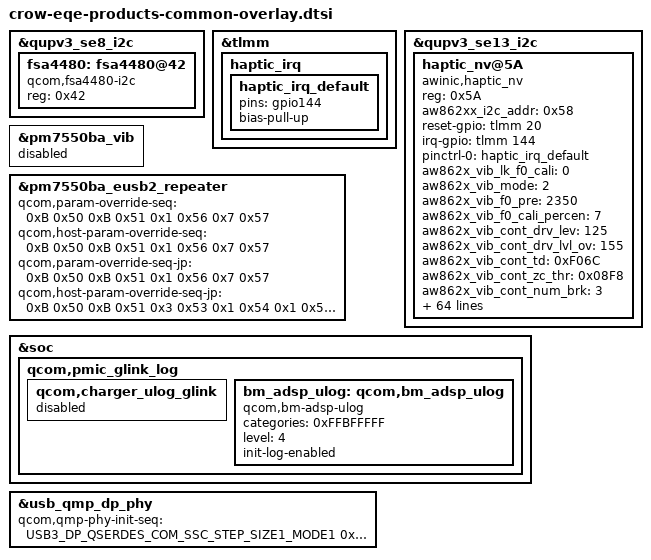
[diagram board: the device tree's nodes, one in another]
/* Copyright (c) 2023, The Linux Foundation. All rights reserved.
 *
 * This program is free software; you can redistribute it and/or modify
 * it under the terms of the GNU General Public License version 2 and
 * only version 2 as published by the Free Software Foundation.
 *
 * This program is distributed in the hope that it will be useful,
 * but WITHOUT ANY WARRANTY; without even the implied warranty of
 * MERCHANTABILITY or FITNESS FOR A PARTICULAR PURPOSE.  See the
 * GNU General Public License for more details.
 */

/*
   This file is used for all rtwo products include prc, row, na etc.
*/

#include "crow-moto-common-overlay-base.dtsi"
#include "crow-moto-common-overlay.dtsi"
#include <dt-bindings/phy/qcom,usb3-4nm-qmp-combo.h>

&qupv3_se8_i2c {
    status = "ok";
    fsa4480: fsa4480@42 {
        compatible = "qcom,fsa4480-i2c";
        reg = <0x42>;
    };
};
&tlmm{
    haptic_irq {
        haptic_irq_default: haptic_irq_default {
            pins = "gpio144";
            bias-pull-up;
        };
    };
};
&qupv3_se13_i2c {
  status = "ok";
  haptic_nv@5A{
		compatible = "awinic,haptic_nv";
		reg = < 0x5A >;
		aw862xx_i2c_addr = < 0x58 >;
		/* aw8624x_no_reset; */
		reset-gpio = <&tlmm 20 0>;
		irq-gpio = <&tlmm 144 0>;
		pinctrl-names = "default";
		pinctrl-0 = <&haptic_irq_default>;
/****************************** aw862x ******************************/
		aw862x_vib_lk_f0_cali = < 0 >;
		aw862x_vib_mode = < 2 >; /* mode: RAM -> 2; CONT -> 3 */
		aw862x_vib_f0_pre = < 2350 >;
		aw862x_vib_f0_cali_percen = < 7 >;
		aw862x_vib_cont_drv_lev = < 125 >;
		aw862x_vib_cont_drv_lvl_ov = < 155 >;
		aw862x_vib_cont_td = < 0xF06C >;
		aw862x_vib_cont_zc_thr = < 0x08F8 >;
		aw862x_vib_cont_num_brk = < 3 >;
		aw862x_vib_f0_coeff = < 260 >; /* Don't modify it */
		aw862x_vib_brake_cont_config = < 1 1 90 42 20 5 2 2 0 0 0 0 0 0 0 0 0 0 0 0 0 0 0 0 >;
		aw862x_vib_f0_trace_parameter = < 0x05 0x03 0x02 0x0F >;
		aw862x_vib_bemf_config = < 0x10 0x08 0x23 0xF8 >;
		aw862x_vib_sw_brake = < 0x2C 0x08 >; /* cont brake, other brake */
		aw862x_vib_trig_config = < 0 1 0 1 1 >;
		aw862x_vib_tset = < 0x11 >;
		aw862x_vib_duration_time = < 20 30 60 >;
/***************************** aw862xx ******************************/
		aw862xx_gain_bypass = < 1 >;
		aw862xx_vib_lk_f0_cali = < 0 >;
		aw862xx_vib_mode = < 2 >; /* mode: RAM -> 2; CONT -> 3 */
		aw862xx_vib_f0_pre = < 2350 >;
		aw862xx_vib_f0_cali_percen = < 7 >;
		aw862xx_vib_cont_drv1_lvl = < 0x7F >;
		aw862xx_vib_lra_vrms = < 1000 >; /* Motor rated voltage, mV */
		aw862xx_vib_cont_brk_time = < 0x06 >;
		aw862xx_vib_cont_brk_gain = < 0x08 >;
		aw862xx_vib_cont_drv1_time = < 0x04 >;
		aw862xx_vib_cont_drv2_time = < 0x14 >;
		aw862xx_vib_cont_track_margin = < 0x0F >;
		aw862xx_vib_d2s_gain = < 0x05 >;
		aw862xx_vib_trig_config = < 0 0 0 1 0 2 0
					    0 0 0 1 0 2 0
					    0 0 0 1 0 2 0 >;
		aw862xx_vib_duration_time = < 20 30 60 >;
		aw862xx_vib_is_enabled_track_en;
		/* aw862xx_vib_is_enabled_auto_brk; */
/***************************** aw8623x ******************************/
		aw8623x_gain_bypass = < 1 >;
		aw8623x_vib_lk_f0_cali = < 0 >;
		aw8623x_vib_mode = < 2 >; /* mode: RAM -> 2; CONT -> 3 */
		aw8623x_vib_f0_pre = < 2350 >;
		aw8623x_vib_f0_cali_percen = < 7 >;
		aw8623x_vib_cont_drv1_lvl = < 0x7F >;
		aw8623x_vib_lra_vrms = < 1000 >; /* Motor rated voltage, mV */
		aw8623x_vib_cont_brk_time = < 0x06 >;
		aw8623x_vib_cont_brk_gain = < 0x08 >;
		aw8623x_vib_cont_drv1_time = < 0x04 >;
		aw8623x_vib_cont_drv2_time = < 0x14 >;
		aw8623x_vib_cont_track_margin = < 0x0F >;
		aw8623x_vib_d2s_gain = < 0x05 >;
		aw8623x_vib_trig_config = < 0 0 0 1 0 2 0
					    0 0 0 1 0 2 0
					    0 0 0 1 0 2 0 >;
		aw8623x_vib_duration_time = < 20 30 60 >;
		aw8623x_vib_is_enabled_track_en;
		/* aw8623x_vib_is_enabled_auto_brk; */
/***************************** aw8624x ******************************/
		aw8624x_gain_bypass = < 1 >;
		aw8624x_vib_lk_f0_cali = < 0 >;
		aw8624x_vib_mode = < 2 >; /* mode: RAM -> 2; CONT -> 3 */
		aw8624x_vib_f0_pre = < 2350 >;
		aw8624x_vib_f0_cali_percen = < 15 >;
		aw8624x_vib_cont_drv1_lvl = < 0x7F >;
		aw8624x_vib_lra_vrms = < 1000 >; /* Motor rated voltage, mV */
		aw8624x_vib_cont_brk_time = < 0x06 >;
		aw8624x_vib_cont_brk_gain = < 0x08 >;
		aw8624x_vib_cont_drv1_time = < 0x04 >;
		aw8624x_vib_cont_drv2_time = < 0x14 >;
		aw8624x_vib_cont_track_margin = < 0x0F >;
		aw8624x_vib_d2s_gain = < 0x05 >;
		aw8624x_vib_f0_d2s_gain = < 0x01 >;
		aw8624x_vib_trig_config = < 0 0 0 1 0 2 0
					    0 0 0 1 0 2 0
					    0 0 0 1 0 2 0 >;
		aw8624x_vib_duration_time = < 20 30 60 >;
		aw8624x_vib_is_enabled_track_en;
		aw8624x_vib_is_enabled_smart_loop;
		aw8624x_vib_is_enabled_inter_brake;
		/* aw8624x_vib_is_enabled_auto_brk; */
		status = "okay";
	};
};

&pm7550ba_vib {
        status = "disabled";
};
&pm7550ba_eusb2_repeater {
	qcom,param-override-seq =
		/* <value reg_offset> */
		/* Adjust HS trasmit amplitude */
		/* USB2 crossover */
		<0xB 0x50
		/* IUSB2 */
		 0xB 0x51
		/* EQU */
		 0x1 0x56
		/*PREEM*/
		 0x7 0x57
		>;
	qcom,host-param-override-seq =
		/* <value reg_offset> */
		/* Adjust HS trasmit amplitude */
		/* USB2 crossover */
		<0xB 0x50
		/* IUSB2 */
		 0xB 0x51
		/* EQU */
		 0x1 0x56
		/*PREEM*/
		 0x7 0x57
		>;
	qcom,param-override-seq-jp =
		/* <value reg_offset> */
		/* Adjust HS trasmit amplitude */
		/* USB2 crossover */
		<0xB 0x50
		/* IUSB2 */
		 0xB 0x51
		/* EQU */
		 0x1 0x56
		/*PREEM*/
		 0x7 0x57
		>;
	qcom,host-param-override-seq-jp =
		/* <value reg_offset> */
		/* Adjust HS trasmit amplitude */
		/* USB2 crossover */
		<0xB 0x50
		/* IUSB2 */
		 0xB 0x51
		/* hsdisc */
		 0x3 0x53
		/* squelch */
		 0x1 0x54
		/* EQU */
		 0x1 0x56
		/*PREEM*/
		 0x7 0x57
		>;
};

&soc {
        qcom,pmic_glink_log {
                qcom,charger_ulog_glink {
                        status = "disabled";
                };
                bm_adsp_ulog: qcom,bm_adsp_ulog {
                        compatible = "qcom,bm-adsp-ulog";
                        categories = <0xFFBFFFFF>;
                        level = <4>;
                        init-log-enabled;
                };
        };
};

		&usb_qmp_dp_phy{
			qcom,qmp-phy-init-seq =
			/* <reg_offset, value> */
		       <USB3_DP_QSERDES_COM_SSC_STEP_SIZE1_MODE1 0x55
			USB3_DP_QSERDES_COM_SSC_STEP_SIZE2_MODE1 0x0E
			USB3_DP_QSERDES_COM_CP_CTRL_MODE1 0x02
			USB3_DP_QSERDES_COM_PLL_RCTRL_MODE1 0x16
			USB3_DP_QSERDES_COM_PLL_CCTRL_MODE1 0x36
			USB3_DP_QSERDES_COM_CORECLK_DIV_MODE1 0x04
			USB3_DP_QSERDES_COM_LOCK_CMP1_MODE1 0x2E
			USB3_DP_QSERDES_COM_LOCK_CMP2_MODE1 0x82
			USB3_DP_QSERDES_COM_DEC_START_MODE1 0x04
			USB3_DP_QSERDES_COM_DEC_START_MSB_MODE1 0x01
			USB3_DP_QSERDES_COM_DIV_FRAC_START1_MODE1 0x55
			USB3_DP_QSERDES_COM_DIV_FRAC_START2_MODE1 0xD5
			USB3_DP_QSERDES_COM_DIV_FRAC_START3_MODE1 0x05
			USB3_DP_QSERDES_COM_HSCLK_SEL_1 0x01
			USB3_DP_QSERDES_COM_VCO_TUNE1_MODE1 0x25
			USB3_DP_QSERDES_COM_VCO_TUNE2_MODE1 0x02
			USB3_DP_QSERDES_COM_BIN_VCOCAL_CMP_CODE1_MODE1 0xB7
			USB3_DP_QSERDES_COM_BIN_VCOCAL_CMP_CODE2_MODE1 0x1E
			USB3_DP_QSERDES_COM_BIN_VCOCAL_CMP_CODE1_MODE0 0xB7
			USB3_DP_QSERDES_COM_BIN_VCOCAL_CMP_CODE2_MODE0 0x1E
			USB3_DP_QSERDES_COM_SSC_STEP_SIZE1_MODE0 0x55
			USB3_DP_QSERDES_COM_SSC_STEP_SIZE2_MODE0 0x0E
			USB3_DP_QSERDES_COM_CP_CTRL_MODE0 0x02
			USB3_DP_QSERDES_COM_PLL_RCTRL_MODE0 0x16
			USB3_DP_QSERDES_COM_PLL_CCTRL_MODE0 0x36
			USB3_DP_QSERDES_COM_LOCK_CMP1_MODE0 0x12
			USB3_DP_QSERDES_COM_LOCK_CMP2_MODE0 0x34
			USB3_DP_QSERDES_COM_DEC_START_MODE0 0x04
			USB3_DP_QSERDES_COM_DEC_START_MSB_MODE0 0x01
			USB3_DP_QSERDES_COM_DIV_FRAC_START1_MODE0 0x55
			USB3_DP_QSERDES_COM_DIV_FRAC_START2_MODE0 0xD5
			USB3_DP_QSERDES_COM_DIV_FRAC_START3_MODE0 0x05
			USB3_DP_QSERDES_COM_VCO_TUNE1_MODE0 0x25
			USB3_DP_QSERDES_COM_VCO_TUNE2_MODE0 0x02
			USB3_DP_QSERDES_COM_BG_TIMER 0x0E
			USB3_DP_QSERDES_COM_SSC_EN_CENTER 0x01
			USB3_DP_QSERDES_COM_SSC_PER1 0x31
			USB3_DP_QSERDES_COM_SSC_PER2 0x01
			USB3_DP_QSERDES_COM_SYSCLK_BUF_ENABLE 0x0C
			USB3_DP_QSERDES_COM_SYSCLK_EN_SEL 0x1A
			USB3_DP_QSERDES_COM_LOCK_CMP_CFG 0x14
			USB3_DP_QSERDES_COM_VCO_TUNE_MAP 0x04
			USB3_DP_QSERDES_COM_CORE_CLK_EN 0x20
			USB3_DP_QSERDES_COM_CMN_CONFIG_1 0x04
			USB3_DP_QSERDES_COM_AUTO_GAIN_ADJ_CTRL_1 0xB6
			USB3_DP_QSERDES_COM_AUTO_GAIN_ADJ_CTRL_2 0x4B
			USB3_DP_QSERDES_COM_AUTO_GAIN_ADJ_CTRL_3 0x37
			USB3_DP_QSERDES_COM_ADDITIONAL_MISC 0x0C
			USB3_DP_QSERDES_TXA_TX_DRV_LVL 0x2f
			USB3_DP_QSERDES_TXA_RES_CODE_LANE_TX 0x00
			USB3_DP_QSERDES_TXA_RES_CODE_LANE_RX 0x00
			USB3_DP_QSERDES_TXA_RES_CODE_LANE_OFFSET_TX 0x1F
			USB3_DP_QSERDES_TXA_RES_CODE_LANE_OFFSET_RX 0x09
			USB3_DP_QSERDES_TXA_LANE_MODE_1 0xF5
			USB3_DP_QSERDES_TXA_LANE_MODE_3 0x3F
			USB3_DP_QSERDES_TXA_LANE_MODE_4 0x3F
			USB3_DP_QSERDES_TXA_LANE_MODE_5 0x5F
			USB3_DP_QSERDES_TXA_RCV_DETECT_LVL_2 0x12
			USB3_DP_QSERDES_TXA_PI_QEC_CTRL 0x21
			USB3_DP_QSERDES_RXA_UCDR_FO_GAIN 0x0A
			USB3_DP_QSERDES_RXA_UCDR_SO_GAIN 0x06
			USB3_DP_QSERDES_RXA_UCDR_FASTLOCK_FO_GAIN 0x2F
			USB3_DP_QSERDES_RXA_UCDR_SO_SATURATION_AND_ENABLE 0x7F
			USB3_DP_QSERDES_RXA_UCDR_FASTLOCK_COUNT_LOW 0xFF
			USB3_DP_QSERDES_RXA_UCDR_FASTLOCK_COUNT_HIGH 0x0F
			USB3_DP_QSERDES_RXA_UCDR_PI_CONTROLS 0x99
			USB3_DP_QSERDES_RXA_UCDR_SB2_THRESH1 0x08
			USB3_DP_QSERDES_RXA_UCDR_SB2_THRESH2 0x08
			USB3_DP_QSERDES_RXA_UCDR_SB2_GAIN1 0x00
			USB3_DP_QSERDES_RXA_UCDR_SB2_GAIN2 0x08
			USB3_DP_QSERDES_RXA_AUX_DATA_TCOARSE_TFINE 0xA0
			USB3_DP_QSERDES_RXA_VGA_CAL_CNTRL1 0x54
			USB3_DP_QSERDES_RXA_VGA_CAL_CNTRL2 0x0F
			USB3_DP_QSERDES_RXA_GM_CAL 0x13
			USB3_DP_QSERDES_RXA_RX_EQU_ADAPTOR_CNTRL2 0x0F
			USB3_DP_QSERDES_RXA_RX_EQU_ADAPTOR_CNTRL3 0x4A
			USB3_DP_QSERDES_RXA_RX_EQU_ADAPTOR_CNTRL4 0x0A
			USB3_DP_QSERDES_RXA_RX_IDAC_TSETTLE_LOW 0x07
			USB3_DP_QSERDES_RXA_RX_IDAC_TSETTLE_HIGH 0x00
			USB3_DP_QSERDES_RXA_RX_EQ_OFFSET_ADAPTOR_CNTRL1 0x47
			USB3_DP_QSERDES_RXA_SIGDET_CNTRL 0x04
			USB3_DP_QSERDES_RXA_SIGDET_DEGLITCH_CNTRL 0x0E
			USB3_DP_QSERDES_RXA_RX_MODE_00_LOW 0x3F
			USB3_DP_QSERDES_RXA_RX_MODE_00_HIGH 0xFF
			USB3_DP_QSERDES_RXA_RX_MODE_00_HIGH2 0xFF
			USB3_DP_QSERDES_RXA_RX_MODE_00_HIGH3 0xDF
			USB3_DP_QSERDES_RXA_RX_MODE_00_HIGH4 0xFE
			USB3_DP_QSERDES_RXA_RX_MODE_01_LOW 0xDC
			USB3_DP_QSERDES_RXA_RX_MODE_01_HIGH 0x5C
			USB3_DP_QSERDES_RXA_RX_MODE_01_HIGH2 0x9C
			USB3_DP_QSERDES_RXA_RX_MODE_01_HIGH3 0x1D
			USB3_DP_QSERDES_RXA_RX_MODE_01_HIGH4 0x09
			USB3_DP_QSERDES_RXA_DFE_EN_TIMER 0x04
			USB3_DP_QSERDES_RXA_DFE_CTLE_POST_CAL_OFFSET 0x38
			USB3_DP_QSERDES_RXA_DCC_CTRL1 0x0C
			USB3_DP_QSERDES_RXA_VTH_CODE 0x10
			USB3_DP_QSERDES_RXA_SIGDET_CAL_CTRL1 0x14
			USB3_DP_QSERDES_RXA_SIGDET_CAL_TRIM 0x08
			USB3_DP_QSERDES_TXB_TX_DRV_LVL 0x2f
			USB3_DP_QSERDES_TXB_RES_CODE_LANE_TX 0x00
			USB3_DP_QSERDES_TXB_RES_CODE_LANE_RX 0x00
			USB3_DP_QSERDES_TXB_RES_CODE_LANE_OFFSET_TX 0x1F
			USB3_DP_QSERDES_TXB_RES_CODE_LANE_OFFSET_RX 0x09
			USB3_DP_QSERDES_TXB_LANE_MODE_1 0xF5
			USB3_DP_QSERDES_TXB_LANE_MODE_3 0x3F
			USB3_DP_QSERDES_TXB_LANE_MODE_4 0x3F
			USB3_DP_QSERDES_TXB_LANE_MODE_5 0x5F
			USB3_DP_QSERDES_TXB_RCV_DETECT_LVL_2 0x12
			USB3_DP_QSERDES_TXB_PI_QEC_CTRL 0x05
			USB3_DP_QSERDES_RXB_UCDR_FO_GAIN 0x0A
			USB3_DP_QSERDES_RXB_UCDR_SO_GAIN 0x06
			USB3_DP_QSERDES_RXB_UCDR_FASTLOCK_FO_GAIN 0x2F
			USB3_DP_QSERDES_RXB_UCDR_SO_SATURATION_AND_ENABLE 0x7F
			USB3_DP_QSERDES_RXB_UCDR_FASTLOCK_COUNT_LOW 0xFF
			USB3_DP_QSERDES_RXB_UCDR_FASTLOCK_COUNT_HIGH 0x0F
			USB3_DP_QSERDES_RXB_UCDR_PI_CONTROLS 0x99
			USB3_DP_QSERDES_RXB_UCDR_SB2_THRESH1 0x08
			USB3_DP_QSERDES_RXB_UCDR_SB2_THRESH2 0x08
			USB3_DP_QSERDES_RXB_UCDR_SB2_GAIN1 0x00
			USB3_DP_QSERDES_RXB_UCDR_SB2_GAIN2 0x08
			USB3_DP_QSERDES_RXB_AUX_DATA_TCOARSE_TFINE 0xA0
			USB3_DP_QSERDES_RXB_VGA_CAL_CNTRL1 0x54
			USB3_DP_QSERDES_RXB_VGA_CAL_CNTRL2 0x0F
			USB3_DP_QSERDES_RXB_GM_CAL 0x13
			USB3_DP_QSERDES_RXB_RX_EQU_ADAPTOR_CNTRL2 0x0F
			USB3_DP_QSERDES_RXB_RX_EQU_ADAPTOR_CNTRL3 0x4A
			USB3_DP_QSERDES_RXB_RX_EQU_ADAPTOR_CNTRL4 0x0A
			USB3_DP_QSERDES_RXB_RX_IDAC_TSETTLE_LOW 0x07
			USB3_DP_QSERDES_RXB_RX_IDAC_TSETTLE_HIGH 0x00
			USB3_DP_QSERDES_RXB_RX_EQ_OFFSET_ADAPTOR_CNTRL1 0x47
			USB3_DP_QSERDES_RXB_SIGDET_CNTRL 0x04
			USB3_DP_QSERDES_RXB_SIGDET_DEGLITCH_CNTRL 0x0E
			USB3_DP_QSERDES_RXB_RX_MODE_00_LOW 0x3F
			USB3_DP_QSERDES_RXB_RX_MODE_00_HIGH 0xFF
			USB3_DP_QSERDES_RXB_RX_MODE_00_HIGH2 0xFF
			USB3_DP_QSERDES_RXB_RX_MODE_00_HIGH3 0xDF
			USB3_DP_QSERDES_RXB_RX_MODE_00_HIGH4 0xFE
			USB3_DP_QSERDES_RXB_RX_MODE_01_LOW 0xDC
			USB3_DP_QSERDES_RXB_RX_MODE_01_HIGH 0x5C
			USB3_DP_QSERDES_RXB_RX_MODE_01_HIGH2 0x9C
			USB3_DP_QSERDES_RXB_RX_MODE_01_HIGH3 0x1D
			USB3_DP_QSERDES_RXB_RX_MODE_01_HIGH4 0x09
			USB3_DP_QSERDES_RXB_DFE_EN_TIMER 0x04
			USB3_DP_QSERDES_RXB_DFE_CTLE_POST_CAL_OFFSET 0x38
			USB3_DP_QSERDES_RXB_DCC_CTRL1 0x0C
			USB3_DP_QSERDES_RXB_VTH_CODE 0x10
			USB3_DP_QSERDES_RXB_SIGDET_CAL_CTRL1 0x14
			USB3_DP_QSERDES_RXB_SIGDET_CAL_TRIM 0x08
			USB3_DP_PCS_LOCK_DETECT_CONFIG1 0xC4
			USB3_DP_PCS_LOCK_DETECT_CONFIG2 0x89
			USB3_DP_PCS_LOCK_DETECT_CONFIG3 0x20
			USB3_DP_PCS_LOCK_DETECT_CONFIG6 0x13
			USB3_DP_PCS_REFGEN_REQ_CONFIG1 0x21
			USB3_DP_PCS_G12S1_TXMGN_V0 0x18
			USB3_DP_PCS_RX_SIGDET_LVL 0x99
			USB3_DP_PCS_RCVR_DTCT_DLY_P1U2_L 0xE7
			USB3_DP_PCS_RCVR_DTCT_DLY_P1U2_H 0x03
			USB3_DP_PCS_CDR_RESET_TIME 0x0A
			USB3_DP_PCS_ALIGN_DETECT_CONFIG1 0x88
			USB3_DP_PCS_ALIGN_DETECT_CONFIG2 0x13
			USB3_DP_PCS_PCS_TX_RX_CONFIG 0x0C
			USB3_DP_PCS_EQ_CONFIG1 0x4B
			USB3_DP_PCS_EQ_CONFIG5 0x10
			USB3_DP_PCS_USB3_POWER_STATE_CONFIG1 0x68
			USB3_DP_PCS_USB3_LFPS_DET_HIGH_COUNT_VAL 0xF8
			USB3_DP_PCS_USB3_RXEQTRAINING_DFE_TIME_S2 0x07
			USB3_DP_PCS_USB3_RCVR_DTCT_DLY_U3_L 0x40
			USB3_DP_PCS_USB3_RCVR_DTCT_DLY_U3_H 0x00>;
	};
